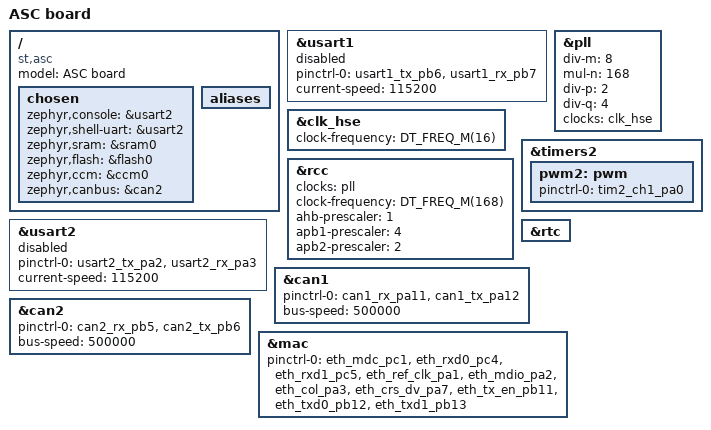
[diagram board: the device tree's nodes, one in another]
/*
 * Copyright (c) 2017 Linaro Limited
 *
 * SPDX-License-Identifier: Apache-2.0
 */

 /dts-v1/;
 #include <st/f4/stm32f407Xg.dtsi>
 #include <st/f4/stm32f407v(e-g)tx-pinctrl.dtsi>
 
 / {
     model = "ASC board";
     compatible = "st,asc";
 
     chosen {
         zephyr,console = &usart2;
         zephyr,shell-uart = &usart2;
         zephyr,sram = &sram0;
         zephyr,flash = &flash0;
         zephyr,ccm = &ccm0;
         zephyr,canbus = &can2;
     };
 
     aliases {

     };
 };
 
 &usart1 {
     pinctrl-0 = <&usart1_tx_pb6 &usart1_rx_pb7>;
     pinctrl-names = "default";
     current-speed = <115200>;
     status = "disabled";
 };
 
 &clk_hse {
     clock-frequency = <DT_FREQ_M(16)>;
     status = "okay";
 };
 
 &pll {
     div-m = <8>;
     mul-n = <168>;
     div-p = <2>;
     div-q = <4>;
     clocks = <&clk_hse>;
     status = "okay";
 };
 
 &rcc {
     clocks = <&pll>;
     clock-frequency = <DT_FREQ_M(168)>;
     ahb-prescaler = <1>;
     apb1-prescaler = <4>;
     apb2-prescaler = <2>;
 };
 
 &usart2 {
     pinctrl-0 = <&usart2_tx_pa2 &usart2_rx_pa3>;
     pinctrl-names = "default";
     current-speed = <115200>;
     status = "disabled";
 };
 
 &timers2 {
     status = "okay";
 
     pwm2: pwm {
         status = "okay";
         pinctrl-0 = <&tim2_ch1_pa0>;
         pinctrl-names = "default";
     };
 };
 
 &rtc {
     status = "okay";
 };
 
 &can1 {
     pinctrl-0 = <&can1_rx_pa11 &can1_tx_pa12>;
     pinctrl-names = "default";
     bus-speed = <500000>;
     status = "okay";
 };
 
 &can2 {
     pinctrl-0 = <&can2_rx_pb5 &can2_tx_pb6>;
     pinctrl-names = "default";
     bus-speed = <500000>;
     status = "okay";
 };

 &mac {
	status = "okay";
	pinctrl-0 = <&eth_mdc_pc1
		     &eth_rxd0_pc4
		     &eth_rxd1_pc5
		     &eth_ref_clk_pa1
		     &eth_mdio_pa2
		     &eth_col_pa3
		     &eth_crs_dv_pa7
		     &eth_tx_en_pb11
		     &eth_txd0_pb12
		     &eth_txd1_pb13>;
	pinctrl-names = "default";
};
